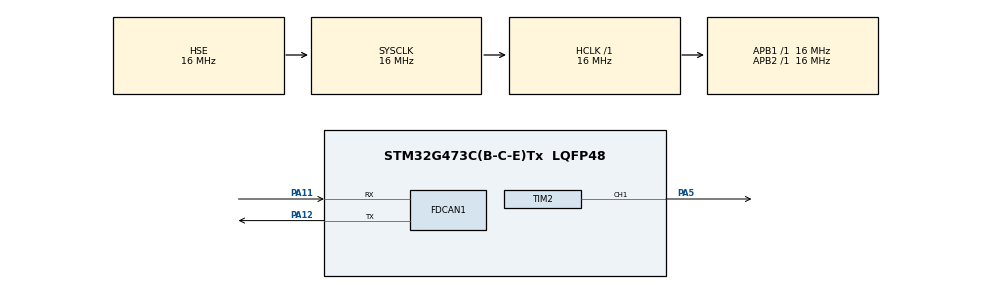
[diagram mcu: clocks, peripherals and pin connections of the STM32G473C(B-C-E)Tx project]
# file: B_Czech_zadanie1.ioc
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FDCAN1.AutoRetransmission=ENABLE
FDCAN1.CalculateBaudRateNominal=1000000
FDCAN1.CalculateTimeBitNominal=1000
FDCAN1.CalculateTimeQuantumNominal=62.5
FDCAN1.NominalPrescaler=1
FDCAN1.NominalTimeSeg1=7
FDCAN1.NominalTimeSeg2=8
Mcu.Family=STM32G4
Mcu.Name=STM32G473C(B-C-E)Tx
Mcu.Package=LQFP48
NVIC.PriorityGroup=NVIC_PRIORITYGROUP_4
PA11.Mode=FDCAN_Activate
PA11.Signal=FDCAN1_RX
PA12.Mode=FDCAN_Activate
PA12.Signal=FDCAN1_TX
PA5.Signal=S_TIM2_CH1
PF0-OSC_IN.Mode=HSE-External-Oscillator
PF0-OSC_IN.Signal=RCC_OSC_IN
PF1-OSC_OUT.Mode=HSE-External-Oscillator
PF1-OSC_OUT.Signal=RCC_OSC_OUT
ProjectManager.HeapSize=0x200
ProjectManager.StackSize=0x400
ProjectManager.TargetToolchain=STM32CubeIDE
RCC.ADC12Freq_Value=16000000
RCC.ADC345Freq_Value=16000000
RCC.AHBFreq_Value=16000000
RCC.APB1Freq_Value=16000000
RCC.APB1TimFreq_Value=16000000
RCC.APB2Freq_Value=16000000
RCC.APB2TimFreq_Value=16000000
RCC.CortexFreq_Value=16000000
RCC.EXTERNAL_CLOCK_VALUE=12288000
RCC.HCLKFreq_Value=16000000
RCC.HSE_VALUE=16000000
RCC.HSI48_VALUE=48000000
RCC.HSI_VALUE=16000000
RCC.LSE_VALUE=32768
RCC.PLLSourceVirtual=RCC_PLLSOURCE_HSE
RCC.SYSCLKFreq_VALUE=16000000
RCC.SYSCLKSource=RCC_SYSCLKSOURCE_HSE
RCC.USBFreq_Value=64000000
RCC.VCOOutputFreq_Value=128000000
SH.S_TIM2_CH1.0=TIM2_CH1,PWM Generation1 CH1
TIM2.Channel-PWM\ Generation1\ CH1=TIM_CHANNEL_1
TIM2.PeriodNoDither=1999
TIM2.Prescaler=1599
TIM2.PulseNoDither_1=1000
VP_IWDG_VS_IWDG.Mode=IWDG_Activate
VP_SYS_VS_DBSignals.Mode=DisableDeadBatterySignals
board=custom

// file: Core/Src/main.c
/* USER CODE BEGIN Header */
/**
  ******************************************************************************
  * @file           : main.c
  * @brief          : Main program body
  ******************************************************************************
  * @attention
  *
  * Copyright (c) 2026 STMicroelectronics.
  * All rights reserved.
  *
  * This software is licensed under terms that can be found in the LICENSE file
  * in the root directory of this software component.
  * If no LICENSE file comes with this software, it is provided AS-IS.
  *
  ******************************************************************************
  */
/* USER CODE END Header */
#include "main.h"

FDCAN_HandleTypeDef hfdcan1;

IWDG_HandleTypeDef hiwdg;

TIM_HandleTypeDef htim2;

void SystemClock_Config(void);
static void MX_GPIO_Init(void);
static void MX_FDCAN1_Init(void);
static void MX_IWDG_Init(void);
static void MX_TIM2_Init(void);

int main(void)
{

  /* MCU Configuration--------------------------------------------------------*/

  /* Reset of all peripherals, Initializes the Flash interface and the Systick. */
  HAL_Init();

  /* Configure the system clock */
  SystemClock_Config();

  /* Initialize all configured peripherals */
  MX_GPIO_Init();
  MX_FDCAN1_Init();
  MX_IWDG_Init();
  MX_TIM2_Init();
  /* USER CODE BEGIN 2 */

  /* txHeader Configuration */

  FDCAN_TxHeaderTypeDef txHeader = {0};

  txHeader.Identifier = 0x738; 						// wymagane w zdaniu ID ramki
  txHeader.IdType = FDCAN_STANDARD_ID;				// standardowy, 11 bitowy format
  txHeader.TxFrameType = FDCAN_DATA_FRAME;			// ramka ma wysylac dane
  txHeader.DataLength = FDCAN_DLC_BYTES_2; 			// dlugosc ramki 2 bajty
  txHeader.FDFormat = FDCAN_CLASSIC_CAN;			// klasycze CAN, a nie FDCAN
  txHeader.BitRateSwitch = FDCAN_BRS_OFF; 			// zmiana szybkości arbitrazu i transmisji dnaych, pozstaje wylaczona
  txHeader.ErrorStateIndicator = FDCAN_ESI_ACTIVE; 	// obsluguje bledy, moze zmianac stany na np. Error Passive
  txHeader.TxEventFifoControl = FDCAN_NO_TX_EVENTS; // kontrola wyslania, mysle ze nie jest to na razie konieczne
  txHeader.MessageMarker = 0; 						// 0 bo nie uzywam tx events

  /* Data_2_Bytes_Bufor */
  uint8_t txData[2] = {0};

  /* CAN_Start */
   if(HAL_FDCAN_Start(&hfdcan1) != HAL_OK)
   {												// kiedy start CAN sie nie powiedzie
  	  Error_Handler();								// fuckja wejdzie w pusta pentle i przepełni iwdg
   }

  /* PWM_Start */
  if(HAL_TIM_PWM_Start(&htim2, TIM_CHANNEL_1) != HAL_OK)
  {
	  Error_Handler();
  }

  /* variable */
  uint32_t lastTime = 0;
  uint16_t upTime = 0;

  /* USER CODE END 2 */

  /* Infinite loop */
  /* USER CODE BEGIN WHILE */

  /* IWDG Refresh */
  HAL_IWDG_Refresh(&hiwdg);

  while (1)
  {
    /* USER CODE END WHILE */

	  /* USER CODE BEGIN 3 */

	  uint32_t currentTime = HAL_GetTick();

	  if((currentTime-lastTime)>= 1000)
	  {
		  upTime++;

		  txData[0] = upTime >> 8;					// przesuniecie bitowe o 8 pozcyji, aby wydobyc starsze bity
		  txData[1]	= upTime & 255; 				// zastosowanie bitmaski, aby wydobyc mlodsze bity

		  if(HAL_FDCAN_GetTxFifoFreeLevel(&hfdcan1) > 0)
		  {
			  if(HAL_FDCAN_AddMessageToTxFifoQ(&hfdcan1, &txHeader, txData) != HAL_OK)
			  {
				  Error_Handler();
			  }

		  }

		  lastTime += 1000;
	   }

	  HAL_IWDG_Refresh(&hiwdg);
  }
  /* USER CODE END 3 */
}

void SystemClock_Config(void)
{
  RCC_OscInitTypeDef RCC_OscInitStruct = {0};
  RCC_ClkInitTypeDef RCC_ClkInitStruct = {0};

  /** Configure the main internal regulator output voltage
  */
  HAL_PWREx_ControlVoltageScaling(PWR_REGULATOR_VOLTAGE_SCALE1);

  /** Initializes the RCC Oscillators according to the specified parameters
  * in the RCC_OscInitTypeDef structure.
  */
  RCC_OscInitStruct.OscillatorType = RCC_OSCILLATORTYPE_LSI|RCC_OSCILLATORTYPE_HSE;
  RCC_OscInitStruct.HSEState = RCC_HSE_ON;
  RCC_OscInitStruct.LSIState = RCC_LSI_ON;
  RCC_OscInitStruct.PLL.PLLState = RCC_PLL_NONE;
  if (HAL_RCC_OscConfig(&RCC_OscInitStruct) != HAL_OK)
  {
    Error_Handler();
  }

  /** Initializes the CPU, AHB and APB buses clocks
  */
  RCC_ClkInitStruct.ClockType = RCC_CLOCKTYPE_HCLK|RCC_CLOCKTYPE_SYSCLK
                              |RCC_CLOCKTYPE_PCLK1|RCC_CLOCKTYPE_PCLK2;
  RCC_ClkInitStruct.SYSCLKSource = RCC_SYSCLKSOURCE_HSE;
  RCC_ClkInitStruct.AHBCLKDivider = RCC_SYSCLK_DIV1;
  RCC_ClkInitStruct.APB1CLKDivider = RCC_HCLK_DIV1;
  RCC_ClkInitStruct.APB2CLKDivider = RCC_HCLK_DIV1;

  if (HAL_RCC_ClockConfig(&RCC_ClkInitStruct, FLASH_LATENCY_0) != HAL_OK)
  {
    Error_Handler();
  }
}

static void MX_FDCAN1_Init(void)
{

  hfdcan1.Instance = FDCAN1;
  hfdcan1.Init.ClockDivider = FDCAN_CLOCK_DIV1;
  hfdcan1.Init.FrameFormat = FDCAN_FRAME_CLASSIC;
  hfdcan1.Init.Mode = FDCAN_MODE_NORMAL;
  hfdcan1.Init.AutoRetransmission = ENABLE;
  hfdcan1.Init.TransmitPause = DISABLE;
  hfdcan1.Init.ProtocolException = DISABLE;
  hfdcan1.Init.NominalPrescaler = 1;
  hfdcan1.Init.NominalSyncJumpWidth = 1;
  hfdcan1.Init.NominalTimeSeg1 = 7;
  hfdcan1.Init.NominalTimeSeg2 = 8;
  hfdcan1.Init.DataPrescaler = 1;
  hfdcan1.Init.DataSyncJumpWidth = 1;
  hfdcan1.Init.DataTimeSeg1 = 1;
  hfdcan1.Init.DataTimeSeg2 = 1;
  hfdcan1.Init.StdFiltersNbr = 0;
  hfdcan1.Init.ExtFiltersNbr = 0;
  hfdcan1.Init.TxFifoQueueMode = FDCAN_TX_FIFO_OPERATION;
  if (HAL_FDCAN_Init(&hfdcan1) != HAL_OK)
  {
    Error_Handler();
  }

}

static void MX_IWDG_Init(void)
{

  hiwdg.Instance = IWDG;
  hiwdg.Init.Prescaler = IWDG_PRESCALER_4;
  hiwdg.Init.Window = 4095;
  hiwdg.Init.Reload = 4095;
  if (HAL_IWDG_Init(&hiwdg) != HAL_OK)
  {
    Error_Handler();
  }

}

static void MX_TIM2_Init(void)
{

  TIM_MasterConfigTypeDef sMasterConfig = {0};
  TIM_OC_InitTypeDef sConfigOC = {0};

  htim2.Instance = TIM2;
  htim2.Init.Prescaler = 1599;
  htim2.Init.CounterMode = TIM_COUNTERMODE_UP;
  htim2.Init.Period = 1999;
  htim2.Init.ClockDivision = TIM_CLOCKDIVISION_DIV1;
  htim2.Init.AutoReloadPreload = TIM_AUTORELOAD_PRELOAD_DISABLE;
  if (HAL_TIM_PWM_Init(&htim2) != HAL_OK)
  {
    Error_Handler();
  }
  sMasterConfig.MasterOutputTrigger = TIM_TRGO_RESET;
  sMasterConfig.MasterSlaveMode = TIM_MASTERSLAVEMODE_DISABLE;
  if (HAL_TIMEx_MasterConfigSynchronization(&htim2, &sMasterConfig) != HAL_OK)
  {
    Error_Handler();
  }
  sConfigOC.OCMode = TIM_OCMODE_PWM1;
  sConfigOC.Pulse = 1000;
  sConfigOC.OCPolarity = TIM_OCPOLARITY_HIGH;
  sConfigOC.OCFastMode = TIM_OCFAST_DISABLE;
  if (HAL_TIM_PWM_ConfigChannel(&htim2, &sConfigOC, TIM_CHANNEL_1) != HAL_OK)
  {
    Error_Handler();
  }
  HAL_TIM_MspPostInit(&htim2);

}

static void MX_GPIO_Init(void)
{

  /* GPIO Ports Clock Enable */
  __HAL_RCC_GPIOF_CLK_ENABLE();
  __HAL_RCC_GPIOA_CLK_ENABLE();

}

void Error_Handler(void)
{
  __disable_irq();
  while (1)
  {
  }
}
